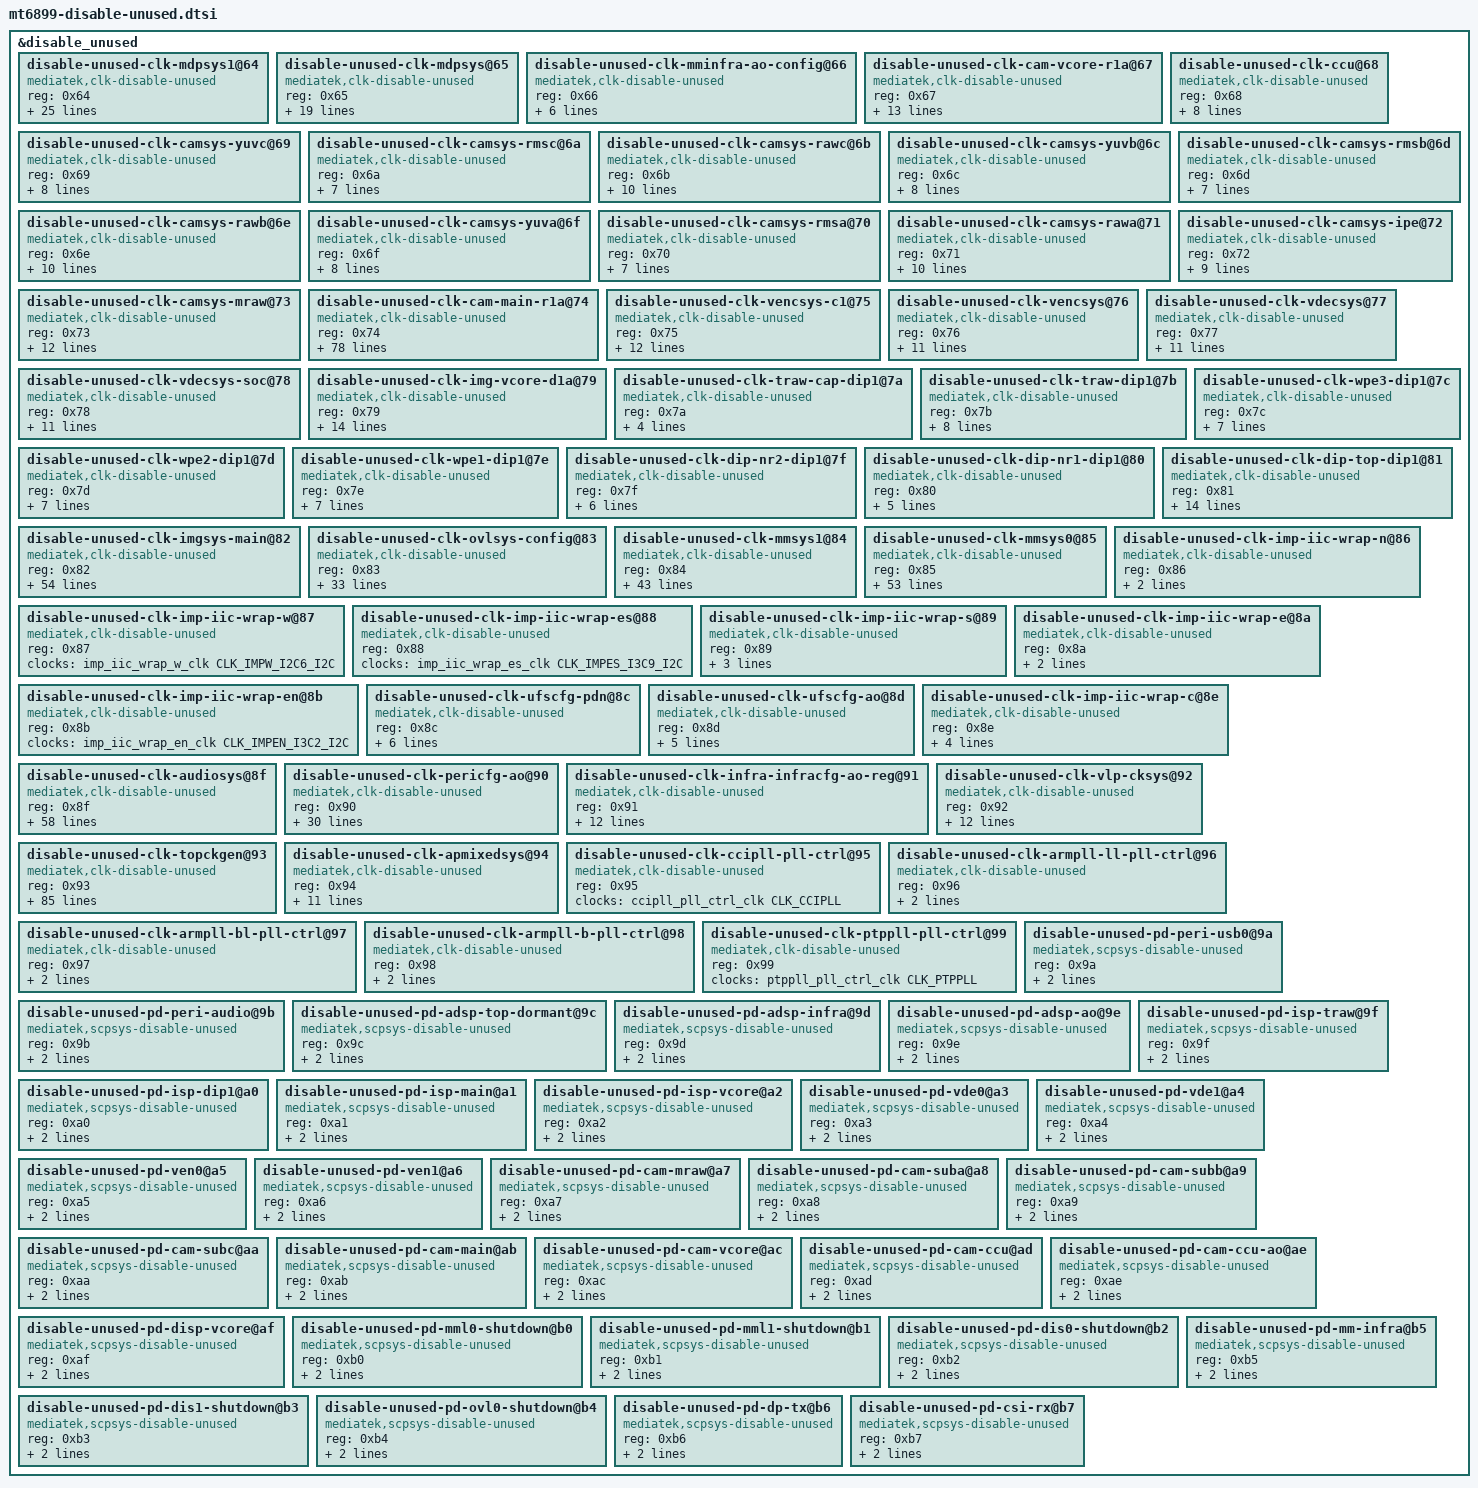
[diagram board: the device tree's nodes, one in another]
// SPDX-License-Identifier: (GPL-2.0 OR MIT)
/*
 * Copyright (C) 2024 MediaTek Inc.
 * Author: KY Liu <ky.liu@mediatek.com>
 */

&disable_unused {
	status = "okay";
	disable-unused-clk-mdpsys1@64 {
		compatible = "mediatek,clk-disable-unused";
		reg = <0x64>;
		clocks =
			<&mdpsys1_config_clk CLK_MDP1_MDP_MUTEX0_MML>,
			<&mdpsys1_config_clk CLK_MDP1_APB_BUS_MML>,
			<&mdpsys1_config_clk CLK_MDP1_SMI0_MML>,
			<&mdpsys1_config_clk CLK_MDP1_SMI0_SMI>,
			<&mdpsys1_config_clk CLK_MDP1_SMI0_GENPD>,
			<&mdpsys1_config_clk CLK_MDP1_MDP_RDMA0_MML>,
			<&mdpsys1_config_clk CLK_MDP1_MDP_RDMA2_MML>,
			<&mdpsys1_config_clk CLK_MDP1_MDP_HDR0_MML>,
			<&mdpsys1_config_clk CLK_MDP1_MDP_AAL0_MML>,
			<&mdpsys1_config_clk CLK_MDP1_MDP_RSZ0_MML>,
			<&mdpsys1_config_clk CLK_MDP1_MDP_TDSHP0_MML>,
			<&mdpsys1_config_clk CLK_MDP1_MDP_COLOR0_MML>,
			<&mdpsys1_config_clk CLK_MDP1_MDP_WROT0_MML>,
			<&mdpsys1_config_clk CLK_MDP1_MDP_FAKE_ENG0_MML>,
			<&mdpsys1_config_clk CLK_MDP1_MDP_DLI_ASYNC0_MML>,
			<&mdpsys1_config_clk CLK_MDP1_APB_DB_MML>,
			<&mdpsys1_config_clk CLK_MDP1_MDP_RSZ2_MML>,
			<&mdpsys1_config_clk CLK_MDP1_MDP_WROT2_MML>,
			<&mdpsys1_config_clk CLK_MDP1_MDP_DLO_ASYNC0_MML>,
			<&mdpsys1_config_clk CLK_MDP1_MDP_BIRSZ0_MML>,
			<&mdpsys1_config_clk CLK_MDP1_MDP_C3D0_MML>,
			<&mdpsys1_config_clk CLK_MDP1_MDP_FG0_MML>;
		power-domains = <&hfrpsys MT6899_POWER_DOMAIN_MML1_SHUTDOWN>;
	};

	disable-unused-clk-mdpsys@65 {
		compatible = "mediatek,clk-disable-unused";
		reg = <0x65>;
		clocks =
			<&mdpsys_config_clk CLK_MDP_MUTEX0_MML>,
			<&mdpsys_config_clk CLK_MDP_APB_BUS_MML>,
			<&mdpsys_config_clk CLK_MDP_SMI0_MML>,
			<&mdpsys_config_clk CLK_MDP_SMI0_SMI>,
			<&mdpsys_config_clk CLK_MDP_SMI0_GENPD>,
			<&mdpsys_config_clk CLK_MDP_RDMA0_MML>,
			<&mdpsys_config_clk CLK_MDP_RDMA2_MML>,
			<&mdpsys_config_clk CLK_MDP_HDR0_MML>,
			<&mdpsys_config_clk CLK_MDP_AAL0_MML>,
			<&mdpsys_config_clk CLK_MDP_RSZ0_MML>,
			<&mdpsys_config_clk CLK_MDP_TDSHP0_MML>,
			<&mdpsys_config_clk CLK_MDP_COLOR0_MML>,
			<&mdpsys_config_clk CLK_MDP_WROT0_MML>,
			<&mdpsys_config_clk CLK_MDP_FAKE_ENG0_MML>,
			<&mdpsys_config_clk CLK_MDP_APB_DB_MML>,
			<&mdpsys_config_clk CLK_MDP_BIRSZ0_MML>,
			<&mdpsys_config_clk CLK_MDP_C3D0_MML>;
		power-domains = <&hfrpsys MT6899_POWER_DOMAIN_MML0_SHUTDOWN>;
	};

	disable-unused-clk-mminfra-ao-config@66 {
		compatible = "mediatek,clk-disable-unused";
		reg = <0x66>;
		clocks =
			<&mminfra_ao_config_clk CLK_MMINFRA_AO_GCE_D_CMDQ>,
			<&mminfra_ao_config_clk CLK_MMINFRA_AO_GCE_M_CMDQ>,
			<&mminfra_ao_config_clk CLK_MMINFRA_AO_GCE_26M_CMDQ>;
		power-domains = <&hfrpsys MT6899_POWER_DOMAIN_MM_INFRA>;
	};

	disable-unused-clk-cam-vcore-r1a@67 {
		compatible = "mediatek,clk-disable-unused";
		reg = <0x67>;
		clocks =
			<&cam_vcore_r1a_clk CLK_CAMV_CV_CAMVCORE_CAMRAW>,
			<&cam_vcore_r1a_clk CLK_CAMV_CV_CAMVCORE_CAM_SENINF>,
			<&cam_vcore_r1a_clk CLK_CAMV_CV_CAM_26M_CAMRAW>,
			<&cam_vcore_r1a_clk CLK_CAMV_CV_CAM_26M_CAM_SENINF>,
			<&cam_vcore_r1a_clk CLK_CAMV_CV_CAM2MM0_SC_DCM_DIS_CAMRAW>,
			<&cam_vcore_r1a_clk CLK_CAMV_CV_CAM2MM0_SC_DCM_DIS_CAM_SENINF>,
			<&cam_vcore_r1a_clk CLK_CAMV_CV_MM0_SC_DCM_DIS_CCU>,
			<&cam_vcore_r1a_clk CLK_CAMV_CV_MM0_SC_DCM_DIS_CAMRAW>,
			<&cam_vcore_r1a_clk CLK_CAMV_CV_MM0_SC_DCM_DIS_CAM_SENINF>,
			<&cam_vcore_r1a_clk CLK_CAMV_CV_MM0_SC_DCM_DIS_SMI>;
		power-domains = <&hfrpsys MT6899_POWER_DOMAIN_CAM_MAIN>;
	};

	disable-unused-clk-ccu@68 {
		compatible = "mediatek,clk-disable-unused";
		reg = <0x68>;
		clocks =
			<&ccu_main_clk CLK_CCU_LARB19_CON_CCU>,
			<&ccu_main_clk CLK_CCU_LARB19_CON_SMI>,
			<&ccu_main_clk CLK_CCU_LARB19_CON_GENPD>,
			<&ccu_main_clk CLK_CCU2INFRA_GALS_CON_CCU>,
			<&ccu_main_clk CLK_CCUSYS_CCU0_CON_CCU0>,
			<&ccu_main_clk CLK_CCU2MM0_GALS_CON_CCU>;
		power-domains = <&hfrpsys MT6899_POWER_DOMAIN_CAM_VCORE>;
	};

	disable-unused-clk-camsys-yuvc@69 {
		compatible = "mediatek,clk-disable-unused";
		reg = <0x69>;
		clocks =
			<&camsys_yuvc_clk CLK_CAM_YC_LARBX_CAMRAWC>,
			<&camsys_yuvc_clk CLK_CAM_YC_LARBX_SMI>,
			<&camsys_yuvc_clk CLK_CAM_YC_LARBX_GENPD>,
			<&camsys_yuvc_clk CLK_CAM_YC_CAM_CAMRAWC>,
			<&camsys_yuvc_clk CLK_CAM_YC_CAMTG_CAMRAWC>;
		power-domains = <&hfrpsys MT6899_POWER_DOMAIN_CAM_MAIN>;
	};

	disable-unused-clk-camsys-rmsc@6a {
		compatible = "mediatek,clk-disable-unused";
		reg = <0x6a>;
		clocks =
			<&camsys_rmsc_clk CLK_CAMSYS_RMSC_LARBX_CAMRAWC>,
			<&camsys_rmsc_clk CLK_CAMSYS_RMSC_LARBX_SMI>,
			<&camsys_rmsc_clk CLK_CAMSYS_RMSC_CAM_CAMRAWC>,
			<&camsys_rmsc_clk CLK_CAMSYS_RMSC_CAMTG_CAMRAWC>;
		power-domains = <&hfrpsys MT6899_POWER_DOMAIN_CAM_MAIN>;
	};

	disable-unused-clk-camsys-rawc@6b {
		compatible = "mediatek,clk-disable-unused";
		reg = <0x6b>;
		clocks =
			<&camsys_rawc_clk CLK_CAM_RC_LARBX_CAMRAWC>,
			<&camsys_rawc_clk CLK_CAM_RC_LARBX_SMI>,
			<&camsys_rawc_clk CLK_CAM_RC_LARBX_GENPD>,
			<&camsys_rawc_clk CLK_CAM_RC_CAM_CAMRAWC>,
			<&camsys_rawc_clk CLK_CAM_RC_CAMTG_CAMRAWC>,
			<&camsys_rawc_clk CLK_CAM_RC_RAW2MM_GALS_CAMRAWC>,
			<&camsys_rawc_clk CLK_CAM_RC_YUV2RAW2MM_GALS_CAMRAWC>;
		power-domains = <&hfrpsys MT6899_POWER_DOMAIN_CAM_MAIN>;
	};

	disable-unused-clk-camsys-yuvb@6c {
		compatible = "mediatek,clk-disable-unused";
		reg = <0x6c>;
		clocks =
			<&camsys_yuvb_clk CLK_CAM_YB_LARBX_CAMRAWB>,
			<&camsys_yuvb_clk CLK_CAM_YB_LARBX_SMI>,
			<&camsys_yuvb_clk CLK_CAM_YB_LARBX_GENPD>,
			<&camsys_yuvb_clk CLK_CAM_YB_CAM_CAMRAWB>,
			<&camsys_yuvb_clk CLK_CAM_YB_CAMTG_CAMRAWB>;
		power-domains = <&hfrpsys MT6899_POWER_DOMAIN_CAM_MAIN>;
	};

	disable-unused-clk-camsys-rmsb@6d {
		compatible = "mediatek,clk-disable-unused";
		reg = <0x6d>;
		clocks =
			<&camsys_rmsb_clk CLK_CAMSYS_RMSB_LARBX_CAMRAWB>,
			<&camsys_rmsb_clk CLK_CAMSYS_RMSB_LARBX_SMI>,
			<&camsys_rmsb_clk CLK_CAMSYS_RMSB_CAM_CAMRAWB>,
			<&camsys_rmsb_clk CLK_CAMSYS_RMSB_CAMTG_CAMRAWB>;
		power-domains = <&hfrpsys MT6899_POWER_DOMAIN_CAM_MAIN>;
	};

	disable-unused-clk-camsys-rawb@6e {
		compatible = "mediatek,clk-disable-unused";
		reg = <0x6e>;
		clocks =
			<&camsys_rawb_clk CLK_CAM_RB_LARBX_CAMRAWB>,
			<&camsys_rawb_clk CLK_CAM_RB_LARBX_SMI>,
			<&camsys_rawb_clk CLK_CAM_RB_LARBX_GENPD>,
			<&camsys_rawb_clk CLK_CAM_RB_CAM_CAMRAWB>,
			<&camsys_rawb_clk CLK_CAM_RB_CAMTG_CAMRAWB>,
			<&camsys_rawb_clk CLK_CAM_RB_RAW2MM_GALS_CAMRAWB>,
			<&camsys_rawb_clk CLK_CAM_RB_YUV2RAW2MM_GALS_CAMRAWB>;
		power-domains = <&hfrpsys MT6899_POWER_DOMAIN_CAM_MAIN>;
	};

	disable-unused-clk-camsys-yuva@6f {
		compatible = "mediatek,clk-disable-unused";
		reg = <0x6f>;
		clocks =
			<&camsys_yuva_clk CLK_CAM_YA_LARBX_CAMRAWA>,
			<&camsys_yuva_clk CLK_CAM_YA_LARBX_SMI>,
			<&camsys_yuva_clk CLK_CAM_YA_LARBX_GENPD>,
			<&camsys_yuva_clk CLK_CAM_YA_CAM_CAMRAWA>,
			<&camsys_yuva_clk CLK_CAM_YA_CAMTG_CAMRAWA>;
		power-domains = <&hfrpsys MT6899_POWER_DOMAIN_CAM_MAIN>;
	};

	disable-unused-clk-camsys-rmsa@70 {
		compatible = "mediatek,clk-disable-unused";
		reg = <0x70>;
		clocks =
			<&camsys_rmsa_clk CLK_CAMSYS_RMSA_LARBX_CAMRAWA>,
			<&camsys_rmsa_clk CLK_CAMSYS_RMSA_LARBX_SMI>,
			<&camsys_rmsa_clk CLK_CAMSYS_RMSA_CAM_CAMRAWA>,
			<&camsys_rmsa_clk CLK_CAMSYS_RMSA_CAMTG_CAMRAWA>;
		power-domains = <&hfrpsys MT6899_POWER_DOMAIN_CAM_MAIN>;
	};

	disable-unused-clk-camsys-rawa@71 {
		compatible = "mediatek,clk-disable-unused";
		reg = <0x71>;
		clocks =
			<&camsys_rawa_clk CLK_CAM_RA_LARBX_CAMRAWA>,
			<&camsys_rawa_clk CLK_CAM_RA_LARBX_SMI>,
			<&camsys_rawa_clk CLK_CAM_RA_LARBX_GENPD>,
			<&camsys_rawa_clk CLK_CAM_RA_CAM_CAMRAWA>,
			<&camsys_rawa_clk CLK_CAM_RA_CAMTG_CAMRAWA>,
			<&camsys_rawa_clk CLK_CAM_RA_RAW2MM_GALS_CAMRAWA>,
			<&camsys_rawa_clk CLK_CAM_RA_YUV2RAW2MM_GALS_CAMRAWA>;
		power-domains = <&hfrpsys MT6899_POWER_DOMAIN_CAM_MAIN>;
	};

	disable-unused-clk-camsys-ipe@72 {
		compatible = "mediatek,clk-disable-unused";
		reg = <0x72>;
		clocks =
			<&camsys_ipe_clk CLK_CAMSYS_IPE_LARB19_SMI>,
			<&camsys_ipe_clk CLK_CAMSYS_IPE_LARB19_CAMERA_P2>,
			<&camsys_ipe_clk CLK_CAMSYS_IPE_LARB19_GENPD>,
			<&camsys_ipe_clk CLK_CAMSYS_IPE_DPE_CAMERA_P2>,
			<&camsys_ipe_clk CLK_CAMSYS_IPE_FUS_CAMERA_P2>,
			<&camsys_ipe_clk CLK_CAMSYS_IPE_GALS_CAMERA_P2>;
		power-domains = <&hfrpsys MT6899_POWER_DOMAIN_CAM_MAIN>;
	};

	disable-unused-clk-camsys-mraw@73 {
		compatible = "mediatek,clk-disable-unused";
		reg = <0x73>;
		clocks =
			<&camsys_mraw_clk CLK_CAM_MR_LARBX_PDAF>,
			<&camsys_mraw_clk CLK_CAM_MR_LARBX_SMI>,
			<&camsys_mraw_clk CLK_CAM_MR_LARBX_GENPD>,
			<&camsys_mraw_clk CLK_CAM_MR_GALS_PDAF>,
			<&camsys_mraw_clk CLK_CAM_MR_CAMTG_PDAF>,
			<&camsys_mraw_clk CLK_CAM_MR_MRAW0_PDAF>,
			<&camsys_mraw_clk CLK_CAM_MR_MRAW1_PDAF>,
			<&camsys_mraw_clk CLK_CAM_MR_MRAW2_PDAF>,
			<&camsys_mraw_clk CLK_CAM_MR_PDA0_PDAF>,
			<&camsys_mraw_clk CLK_CAM_MR_PDA1_PDAF>;
		power-domains = <&hfrpsys MT6899_POWER_DOMAIN_CAM_MAIN>;
	};

	disable-unused-clk-cam-main-r1a@74 {
		compatible = "mediatek,clk-disable-unused";
		reg = <0x74>;
		clocks =
			<&cam_main_r1a_clk CLK_CAM_MAIN_LARB13_CAMSV>,
			<&cam_main_r1a_clk CLK_CAM_MAIN_LARB13_SMI>,
			<&cam_main_r1a_clk CLK_CAM_MAIN_LARB13_GENPD>,
			<&cam_main_r1a_clk CLK_CAM_MAIN_LARB14_CAMSV>,
			<&cam_main_r1a_clk CLK_CAM_MAIN_LARB14_SMI>,
			<&cam_main_r1a_clk CLK_CAM_MAIN_LARB14_GENPD>,
			<&cam_main_r1a_clk CLK_CAM_MAIN_LARB27_SMI>,
			<&cam_main_r1a_clk CLK_CAM_MAIN_LARB27_GENPD>,
			<&cam_main_r1a_clk CLK_CAM_MAIN_LARB29_CAMSV>,
			<&cam_main_r1a_clk CLK_CAM_MAIN_LARB29_SMI>,
			<&cam_main_r1a_clk CLK_CAM_MAIN_LARB29_GENPD>,
			<&cam_main_r1a_clk CLK_CAM_MAIN_CAM_CAM_SENINF>,
			<&cam_main_r1a_clk CLK_CAM_MAIN_CAM_CAMRAWA>,
			<&cam_main_r1a_clk CLK_CAM_MAIN_CAM_CAMRAWB>,
			<&cam_main_r1a_clk CLK_CAM_MAIN_CAM_CAMRAWC>,
			<&cam_main_r1a_clk CLK_CAM_MAIN_CAM_CAMSV>,
			<&cam_main_r1a_clk CLK_CAM_MAIN_CAM_SUBA_CAMRAWA>,
			<&cam_main_r1a_clk CLK_CAM_MAIN_CAM_SUBA_GENPD>,
			<&cam_main_r1a_clk CLK_CAM_MAIN_CAM_SUBB_CAMRAWB>,
			<&cam_main_r1a_clk CLK_CAM_MAIN_CAM_SUBB_GENPD>,
			<&cam_main_r1a_clk CLK_CAM_MAIN_CAM_SUBC_CAMRAWC>,
			<&cam_main_r1a_clk CLK_CAM_MAIN_CAM_SUBC_GENPD>,
			<&cam_main_r1a_clk CLK_CAM_MAIN_CAM_MRAW_PDAF>,
			<&cam_main_r1a_clk CLK_CAM_MAIN_CAM_MRAW_GENPD>,
			<&cam_main_r1a_clk CLK_CAM_MAIN_CAMTG_CAM_SENINF>,
			<&cam_main_r1a_clk CLK_CAM_MAIN_CAMTG_CAMRAWA>,
			<&cam_main_r1a_clk CLK_CAM_MAIN_CAMTG_CAMRAWB>,
			<&cam_main_r1a_clk CLK_CAM_MAIN_CAMTG_CAMRAWC>,
			<&cam_main_r1a_clk CLK_CAM_MAIN_SENINF_CAM_SENINF>,
			<&cam_main_r1a_clk CLK_CAM_MAIN_CAMSV_TOP_CAMSV>,
			<&cam_main_r1a_clk CLK_CAM_MAIN_ADLRD_CAMRAWA>,
			<&cam_main_r1a_clk CLK_CAM_MAIN_ADLRD_CAMRAWB>,
			<&cam_main_r1a_clk CLK_CAM_MAIN_ADLRD_CAMRAWC>,
			<&cam_main_r1a_clk CLK_CAM_MAIN_ADLWR_CAMRAWA>,
			<&cam_main_r1a_clk CLK_CAM_MAIN_ADLWR_CAMRAWB>,
			<&cam_main_r1a_clk CLK_CAM_MAIN_ADLWR_CAMRAWC>,
			<&cam_main_r1a_clk CLK_CAM_MAIN_FAKE_ENG_CAMRAW>,
			<&cam_main_r1a_clk CLK_CAM_MAIN_CAM2MM0_GALS_CAMRAWA>,
			<&cam_main_r1a_clk CLK_CAM_MAIN_CAM2MM0_GALS_CAMRAWB>,
			<&cam_main_r1a_clk CLK_CAM_MAIN_CAM2MM0_GALS_CAMRAWC>,
			<&cam_main_r1a_clk CLK_CAM_MAIN_CAM2MM0_GALS_CAMSV>,
			<&cam_main_r1a_clk CLK_CAM_MAIN_CAM2MM0_GALS_PDAF>,
			<&cam_main_r1a_clk CLK_CAM_MAIN_CAM2MM1_GALS_CAMRAWA>,
			<&cam_main_r1a_clk CLK_CAM_MAIN_CAM2MM1_GALS_CAMRAWB>,
			<&cam_main_r1a_clk CLK_CAM_MAIN_CAM2MM1_GALS_CAMRAWC>,
			<&cam_main_r1a_clk CLK_CAM_MAIN_CAM2MM1_GALS_CAMSV>,
			<&cam_main_r1a_clk CLK_CAM_MAIN_CAM2MM1_GALS_PDAF>,
			<&cam_main_r1a_clk CLK_CAM_MAIN_CAM2SYS_GALS_CAMRAWA>,
			<&cam_main_r1a_clk CLK_CAM_MAIN_CAM2SYS_GALS_CAMRAWB>,
			<&cam_main_r1a_clk CLK_CAM_MAIN_CAM2SYS_GALS_CAMRAWC>,
			<&cam_main_r1a_clk CLK_CAM_MAIN_CAM2SYS_GALS_CAMSV>,
			<&cam_main_r1a_clk CLK_CAM_MAIN_CAM2SYS_GALS_PDAF>,
			<&cam_main_r1a_clk CLK_CAM_MAIN_CAM2MM2_GALS_CAMRAWA>,
			<&cam_main_r1a_clk CLK_CAM_MAIN_CAM2MM2_GALS_CAMRAWB>,
			<&cam_main_r1a_clk CLK_CAM_MAIN_CAM2MM2_GALS_CAMRAWC>,
			<&cam_main_r1a_clk CLK_CAM_MAIN_CAM2MM2_GALS_CAMSV>,
			<&cam_main_r1a_clk CLK_CAM_MAIN_CAM2MM2_GALS_PDAF>,
			<&cam_main_r1a_clk CLK_CAM_MAIN_IPS_CAMRAW>,
			<&cam_main_r1a_clk CLK_CAM_MAIN_CAM_DPE_CAMERA_P2>,
			<&cam_main_r1a_clk CLK_CAM_MAIN_CAM_DPE_GENPD>,
			<&cam_main_r1a_clk CLK_CAM_MAIN_CAM_ASG_CAM_SENINF>,
			<&cam_main_r1a_clk CLK_CAM_MAIN_CAMSV_A_CON_1_CAMSV>,
			<&cam_main_r1a_clk CLK_CAM_MAIN_CAMSV_B_CON_1_CAMSV>,
			<&cam_main_r1a_clk CLK_CAM_MAIN_CAMSV_C_CON_1_CAMSV>,
			<&cam_main_r1a_clk CLK_CAM_MAIN_CAMSV_D_CON_1_CAMSV>,
			<&cam_main_r1a_clk CLK_CAM_MAIN_CAMSV_E_CON_1_CAMSV>,
			<&cam_main_r1a_clk CLK_CAM_MAIN_CAM_QOF_CON_1_CAMRAW>,
			<&cam_main_r1a_clk CLK_CAM_MAIN_CAM_BLS_FULL_CON_1_CAMRAW>,
			<&cam_main_r1a_clk CLK_CAM_MAIN_CAM_BLS_PART_CON_1_CAMRAW>,
			<&cam_main_r1a_clk CLK_CAM_MAIN_CAM_BWR_CON_1_CAMBWR>,
			<&cam_main_r1a_clk CLK_CAM_MAIN_CAM_RTCQ_CON_1_CAMRAW>,
			<&cam_main_r1a_clk CLK_CAM_MAIN_CAM2MM0_SUB_COMMON_DCM_DIS_CAMRAW>,
			<&cam_main_r1a_clk CLK_CAM_MAIN_CAM2MM1_SUB_COMMON_DCM_DIS_CAMRAW>,
			<&cam_main_r1a_clk CLK_CAM_MAIN_CAM2SYS_SUB_COMMON_DCM_DIS_CAMRAW>,
			<&cam_main_r1a_clk CLK_CAM_MAIN_CAM2MM2_SUB_COMMON_DCM_DIS_CAMRAW>;
		power-domains = <&hfrpsys MT6899_POWER_DOMAIN_CAM_VCORE>;
	};

	disable-unused-clk-vencsys-c1@75 {
		compatible = "mediatek,clk-disable-unused";
		reg = <0x75>;
		clocks =
			<&venc_gcon_core1_clk CLK_VEN2_CKE0_LARB_VENC>,
			<&venc_gcon_core1_clk CLK_VEN2_CKE0_LARB_SMI>,
			<&venc_gcon_core1_clk CLK_VEN2_CKE1_VENC_VENC>,
			<&venc_gcon_core1_clk CLK_VEN2_CKE2_JPGENC_JPGENC>,
			<&venc_gcon_core1_clk CLK_VEN2_CKE3_JPGDEC_JPGDEC>,
			<&venc_gcon_core1_clk CLK_VEN2_CKE5_GALS_VENC>,
			<&venc_gcon_core1_clk CLK_VEN2_CKE5_GALS_SMI>,
			<&venc_gcon_core1_clk CLK_VEN2_CKE6_GALS_SRAM_VENC>,
			<&venc_gcon_core1_clk CLK_VEN2_CKE6_GALS_SRAM_SMI>;
		power-domains = <&hfrpsys MT6899_POWER_DOMAIN_VEN1>;
	};

	disable-unused-clk-vencsys@76 {
		compatible = "mediatek,clk-disable-unused";
		reg = <0x76>;
		clocks =
			<&venc_gcon_clk CLK_VEN1_CKE0_LARB_SMI>,
			<&venc_gcon_clk CLK_VEN1_CKE1_VENC_VENC>,
			<&venc_gcon_clk CLK_VEN1_CKE2_JPGENC_JPGENC>,
			<&venc_gcon_clk CLK_VEN1_CKE3_JPGDEC_JPGDEC>,
			<&venc_gcon_clk CLK_VEN1_CKE4_JPGDEC_C1_JPGDEC>,
			<&venc_gcon_clk CLK_VEN1_CKE5_GALS_VENC>,
			<&venc_gcon_clk CLK_VEN1_CKE5_GALS_SMI>,
			<&venc_gcon_clk CLK_VEN1_CKE6_GALS_SRAM_VENC>,
			<&venc_gcon_clk CLK_VEN1_CKE6_GALS_SRAM_SMI>;
		power-domains = <&hfrpsys MT6899_POWER_DOMAIN_VEN0>;
	};

	disable-unused-clk-vdecsys@77 {
		compatible = "mediatek,clk-disable-unused";
		reg = <0x77>;
		clocks =
			<&vdec_gcon_base_clk CLK_VDE2_LARB1_CKEN_SMI>,
			<&vdec_gcon_base_clk CLK_VDE2_LARB1_CKEN_GENPD>,
			<&vdec_gcon_base_clk CLK_VDE2_LAT_CKEN_VDEC>,
			<&vdec_gcon_base_clk CLK_VDE2_LAT_ACTIVE_VDEC>,
			<&vdec_gcon_base_clk CLK_VDE2_LAT_CKEN_ENG_VDEC>,
			<&vdec_gcon_base_clk CLK_VDE2_VDEC_CKEN_VDEC>,
			<&vdec_gcon_base_clk CLK_VDE2_VDEC_ACTIVE_VDEC>,
			<&vdec_gcon_base_clk CLK_VDE2_VDEC_CKEN_ENG_VDEC>;
		power-domains = <&hfrpsys MT6899_POWER_DOMAIN_VDE0>;
	};

	disable-unused-clk-vdecsys-soc@78 {
		compatible = "mediatek,clk-disable-unused";
		reg = <0x78>;
		clocks =
			<&vdec_soc_gcon_base_clk CLK_VDE1_LARB1_CKEN_SMI>,
			<&vdec_soc_gcon_base_clk CLK_VDE1_LARB1_CKEN_GENPD>,
			<&vdec_soc_gcon_base_clk CLK_VDE1_LAT_CKEN_VDEC>,
			<&vdec_soc_gcon_base_clk CLK_VDE1_LAT_ACTIVE_VDEC>,
			<&vdec_soc_gcon_base_clk CLK_VDE1_LAT_CKEN_ENG_VDEC>,
			<&vdec_soc_gcon_base_clk CLK_VDE1_VDEC_CKEN_VDEC>,
			<&vdec_soc_gcon_base_clk CLK_VDE1_VDEC_ACTIVE_VDEC>,
			<&vdec_soc_gcon_base_clk CLK_VDE1_VDEC_CKEN_ENG_VDEC>;
		power-domains = <&hfrpsys MT6899_POWER_DOMAIN_VDE1>;
	};

	disable-unused-clk-img-vcore-d1a@79 {
		compatible = "mediatek,clk-disable-unused";
		reg = <0x79>;
		clocks =
			<&img_vcore_d1a_clk CLK_IMG_VCORE_GALS_DISP_CAMERA_P2>,
			<&img_vcore_d1a_clk CLK_IMG_VCORE_GALS_DISP_CAMERA_MAE>,
			<&img_vcore_d1a_clk CLK_IMG_VCORE_MAIN_CAMERA_P2>,
			<&img_vcore_d1a_clk CLK_IMG_VCORE_MAIN_CAMERA_MAE>,
			<&img_vcore_d1a_clk CLK_IMG_VCORE_SUB0_CAMERA_P2>,
			<&img_vcore_d1a_clk CLK_IMG_VCORE_SUB0_CAMERA_MAE>,
			<&img_vcore_d1a_clk CLK_IMG_VCORE_SUB0_SMI>,
			<&img_vcore_d1a_clk CLK_IMG_VCORE_SUB1_CAMERA_P2>,
			<&img_vcore_d1a_clk CLK_IMG_VCORE_SUB1_CAMERA_MAE>,
			<&img_vcore_d1a_clk CLK_IMG_VCORE_SUB1_SMI>,
			<&img_vcore_d1a_clk CLK_IMG_VCORE_IMG_26M_CAMERA_P2>;
		power-domains = <&hfrpsys MT6899_POWER_DOMAIN_ISP_MAIN>;
	};

	disable-unused-clk-traw-cap-dip1@7a {
		compatible = "mediatek,clk-disable-unused";
		reg = <0x7a>;
		clocks =
			<&traw_cap_dip1_clk CLK_TRAW_CAP_DIP1_TRAW_CAP_CAMERA_P2>;
		power-domains = <&hfrpsys MT6899_POWER_DOMAIN_ISP_TRAW>;
	};

	disable-unused-clk-traw-dip1@7b {
		compatible = "mediatek,clk-disable-unused";
		reg = <0x7b>;
		clocks =
			<&traw_dip1_clk CLK_TRAW_DIP1_LARB28_CAMERA_P2>,
			<&traw_dip1_clk CLK_TRAW_DIP1_LARB28_SMI>,
			<&traw_dip1_clk CLK_TRAW_DIP1_LARB40_CAMERA_P2>,
			<&traw_dip1_clk CLK_TRAW_DIP1_TRAW_CAMERA_P2>,
			<&traw_dip1_clk CLK_TRAW_DIP1_GALS_CAMERA_P2>;
		power-domains = <&hfrpsys MT6899_POWER_DOMAIN_ISP_TRAW>;
	};

	disable-unused-clk-wpe3-dip1@7c {
		compatible = "mediatek,clk-disable-unused";
		reg = <0x7c>;
		clocks =
			<&wpe3_dip1_clk CLK_WPE3_DIP1_LARB11_CAMERA_P2>,
			<&wpe3_dip1_clk CLK_WPE3_DIP1_LARB11_SMI>,
			<&wpe3_dip1_clk CLK_WPE3_DIP1_WPE_CAMERA_P2>,
			<&wpe3_dip1_clk CLK_WPE3_DIP1_GALS0_CAMERA_P2>;
		power-domains = <&hfrpsys MT6899_POWER_DOMAIN_ISP_DIP1>;
	};

	disable-unused-clk-wpe2-dip1@7d {
		compatible = "mediatek,clk-disable-unused";
		reg = <0x7d>;
		clocks =
			<&wpe2_dip1_clk CLK_WPE2_DIP1_LARB11_CAMERA_P2>,
			<&wpe2_dip1_clk CLK_WPE2_DIP1_LARB11_SMI>,
			<&wpe2_dip1_clk CLK_WPE2_DIP1_WPE_CAMERA_P2>,
			<&wpe2_dip1_clk CLK_WPE2_DIP1_GALS0_CAMERA_P2>;
		power-domains = <&hfrpsys MT6899_POWER_DOMAIN_ISP_DIP1>;
	};

	disable-unused-clk-wpe1-dip1@7e {
		compatible = "mediatek,clk-disable-unused";
		reg = <0x7e>;
		clocks =
			<&wpe1_dip1_clk CLK_WPE1_DIP1_LARB11_CAMERA_P2>,
			<&wpe1_dip1_clk CLK_WPE1_DIP1_LARB11_SMI>,
			<&wpe1_dip1_clk CLK_WPE1_DIP1_WPE_CAMERA_P2>,
			<&wpe1_dip1_clk CLK_WPE1_DIP1_GALS0_CAMERA_P2>;
		power-domains = <&hfrpsys MT6899_POWER_DOMAIN_ISP_DIP1>;
	};

	disable-unused-clk-dip-nr2-dip1@7f {
		compatible = "mediatek,clk-disable-unused";
		reg = <0x7f>;
		clocks =
			<&dip_nr2_dip1_clk CLK_DIP_NR2_DIP1_DIP_NR_CAMERA_P2>,
			<&dip_nr2_dip1_clk CLK_DIP_NR2_DIP1_LARB15_CAMERA_P2>,
			<&dip_nr2_dip1_clk CLK_DIP_NR2_DIP1_LARB39_CAMERA_P2>;
		power-domains = <&hfrpsys MT6899_POWER_DOMAIN_ISP_DIP1>;
	};

	disable-unused-clk-dip-nr1-dip1@80 {
		compatible = "mediatek,clk-disable-unused";
		reg = <0x80>;
		clocks =
			<&dip_nr1_dip1_clk CLK_DIP_NR1_DIP1_LARB_CAMERA_P2>,
			<&dip_nr1_dip1_clk CLK_DIP_NR1_DIP1_DIP_NR1_CAMERA_P2>;
		power-domains = <&hfrpsys MT6899_POWER_DOMAIN_ISP_DIP1>;
	};

	disable-unused-clk-dip-top-dip1@81 {
		compatible = "mediatek,clk-disable-unused";
		reg = <0x81>;
		clocks =
			<&dip_top_dip1_clk CLK_DIP_TOP_DIP1_DIP_TOP_CAMERA_P2>,
			<&dip_top_dip1_clk CLK_DIP_TOP_DIP1_DIP_TOP_GALS0_CAMERA_P2>,
			<&dip_top_dip1_clk CLK_DIP_TOP_DIP1_DIP_TOP_GALS1_CAMERA_P2>,
			<&dip_top_dip1_clk CLK_DIP_TOP_DIP1_DIP_TOP_GALS2_CAMERA_P2>,
			<&dip_top_dip1_clk CLK_DIP_TOP_DIP1_DIP_TOP_GALS3_CAMERA_P2>,
			<&dip_top_dip1_clk CLK_DIP_TOP_DIP1_LARB10_CAMERA_P2>,
			<&dip_top_dip1_clk CLK_DIP_TOP_DIP1_LARB15_CAMERA_P2>,
			<&dip_top_dip1_clk CLK_DIP_TOP_DIP1_LARB15_SMI>,
			<&dip_top_dip1_clk CLK_DIP_TOP_DIP1_LARB38_CAMERA_P2>,
			<&dip_top_dip1_clk CLK_DIP_TOP_DIP1_LARB38_SMI>,
			<&dip_top_dip1_clk CLK_DIP_TOP_DIP1_LARB39_CAMERA_P2>;
		power-domains = <&hfrpsys MT6899_POWER_DOMAIN_ISP_DIP1>;
	};

	disable-unused-clk-imgsys-main@82 {
		compatible = "mediatek,clk-disable-unused";
		reg = <0x82>;
		clocks =
			<&imgsys_main_clk CLK_IMG_FDVT_CAMERA_MAE>,
			<&imgsys_main_clk CLK_IMG_ME_CAMERA_P2>,
			<&imgsys_main_clk CLK_IMG_MMG_CAMERA_P2>,
			<&imgsys_main_clk CLK_IMG_LARB12_CAMERA_P2>,
			<&imgsys_main_clk CLK_IMG_LARB12_SMI>,
			<&imgsys_main_clk CLK_IMG_LARB12_CAMERA_MAE>,
			<&imgsys_main_clk CLK_IMG_LARB9_CAMERA_P2>,
			<&imgsys_main_clk CLK_IMG_LARB9_SMI>,
			<&imgsys_main_clk CLK_IMG_TRAW0_CAMERA_P2>,
			<&imgsys_main_clk CLK_IMG_TRAW1_CAMERA_P2>,
			<&imgsys_main_clk CLK_IMG_DIP0_CAMERA_P2>,
			<&imgsys_main_clk CLK_IMG_WPE0_CAMERA_P2>,
			<&imgsys_main_clk CLK_IMG_IPE_CAMERA_P2>,
			<&imgsys_main_clk CLK_IMG_IPE_CAMERA_MAE>,
			<&imgsys_main_clk CLK_IMG_WPE1_CAMERA_P2>,
			<&imgsys_main_clk CLK_IMG_WPE2_CAMERA_P2>,
			<&imgsys_main_clk CLK_IMG_ADL_LARB_CAMERA_P2>,
			<&imgsys_main_clk CLK_IMG_ADL_LARB_SMI>,
			<&imgsys_main_clk CLK_IMG_ADLRD_CAMERA_P2>,
			<&imgsys_main_clk CLK_IMG_ADLWR0_CAMERA_P2>,
			<&imgsys_main_clk CLK_IMG_AVS_CAMERA_P2>,
			<&imgsys_main_clk CLK_IMG_IPS_CAMERA_P2>,
			<&imgsys_main_clk CLK_IMG_ADLWR1_CAMERA_P2>,
			<&imgsys_main_clk CLK_IMG_ROOTCQ_CAMERA_P2>,
			<&imgsys_main_clk CLK_IMG_BLS_CAMERA_P2>,
			<&imgsys_main_clk CLK_IMG_SUB_COMMON0_CAMERA_P2>,
			<&imgsys_main_clk CLK_IMG_SUB_COMMON0_SMI>,
			<&imgsys_main_clk CLK_IMG_SUB_COMMON1_CAMERA_P2>,
			<&imgsys_main_clk CLK_IMG_SUB_COMMON1_SMI>,
			<&imgsys_main_clk CLK_IMG_SUB_COMMON2_CAMERA_P2>,
			<&imgsys_main_clk CLK_IMG_SUB_COMMON2_CAMERA_MAE>,
			<&imgsys_main_clk CLK_IMG_SUB_COMMON2_SMI>,
			<&imgsys_main_clk CLK_IMG_SUB_COMMON3_CAMERA_P2>,
			<&imgsys_main_clk CLK_IMG_SUB_COMMON3_CAMERA_MAE>,
			<&imgsys_main_clk CLK_IMG_SUB_COMMON3_SMI>,
			<&imgsys_main_clk CLK_IMG_SUB_COMMON4_CAMERA_P2>,
			<&imgsys_main_clk CLK_IMG_SUB_COMMON4_SMI>,
			<&imgsys_main_clk CLK_IMG_GALS_RX_DIP0_CAMERA_P2>,
			<&imgsys_main_clk CLK_IMG_GALS_RX_DIP1_CAMERA_P2>,
			<&imgsys_main_clk CLK_IMG_GALS_RX_TRAW0_CAMERA_P2>,
			<&imgsys_main_clk CLK_IMG_GALS_RX_WPE0_CAMERA_P2>,
			<&imgsys_main_clk CLK_IMG_GALS_RX_WPE1_CAMERA_P2>,
			<&imgsys_main_clk CLK_IMG_GALS_RX_WPE2_CAMERA_P2>,
			<&imgsys_main_clk CLK_IMG_GALS_TRX_IPE0_CAMERA_P2>,
			<&imgsys_main_clk CLK_IMG_GALS_TRX_IPE0_CAMERA_MAE>,
			<&imgsys_main_clk CLK_IMG_GALS_TRX_IPE1_CAMERA_P2>,
			<&imgsys_main_clk CLK_IMG_GALS_TRX_IPE1_CAMERA_MAE>,
			<&imgsys_main_clk CLK_IMG26_CAMERA_P2>,
			<&imgsys_main_clk CLK_IMG_BWR_CAMERA_P2>,
			<&imgsys_main_clk CLK_IMG_GALS_CAMERA_P2>,
			<&imgsys_main_clk CLK_IMG_GALS_CAMERA_MAE>;
		power-domains = <&hfrpsys MT6899_POWER_DOMAIN_ISP_MAIN>;
	};

	disable-unused-clk-ovlsys-config@83 {
		compatible = "mediatek,clk-disable-unused";
		reg = <0x83>;
		clocks =
			<&ovlsys_config_clk CLK_OVLSYS_CONFIG_DISP>,
			<&ovlsys_config_clk CLK_OVL_DISP_FAKE_ENG0_DISP>,
			<&ovlsys_config_clk CLK_OVL_DISP_FAKE_ENG1_DISP>,
			<&ovlsys_config_clk CLK_OVL_DISP_MUTEX0_DISP>,
			<&ovlsys_config_clk CLK_OVL_DISP_OVL0_2L_DISP>,
			<&ovlsys_config_clk CLK_OVL_DISP_OVL1_2L_DISP>,
			<&ovlsys_config_clk CLK_OVL_DISP_OVL2_2L_DISP>,
			<&ovlsys_config_clk CLK_OVL_DISP_OVL3_2L_DISP>,
			<&ovlsys_config_clk CLK_OVL_DISP_RSZ1_DISP>,
			<&ovlsys_config_clk CLK_OVL_MDP_RSZ0_DISP>,
			<&ovlsys_config_clk CLK_OVL_DISP_WDMA0_DISP>,
			<&ovlsys_config_clk CLK_OVL_DISP_UFBC_WDMA0_DISP>,
			<&ovlsys_config_clk CLK_OVL_DISP_WDMA2_DISP>,
			<&ovlsys_config_clk CLK_OVL_DISP_DLI_ASYNC0_DISP>,
			<&ovlsys_config_clk CLK_OVL_DISP_DLI_ASYNC1_DISP>,
			<&ovlsys_config_clk CLK_OVL_DISP_DLI_ASYNC2_DISP>,
			<&ovlsys_config_clk CLK_OVL_DISP_DL0_ASYNC0_DISP>,
			<&ovlsys_config_clk CLK_OVL_DISP_DL0_ASYNC1_DISP>,
			<&ovlsys_config_clk CLK_OVL_DISP_DL0_ASYNC2_DISP>,
			<&ovlsys_config_clk CLK_OVL_DISP_DL0_ASYNC3_DISP>,
			<&ovlsys_config_clk CLK_OVL_DISP_DL0_ASYNC4_DISP>,
			<&ovlsys_config_clk CLK_OVL_DISP_DL0_ASYNC5_DISP>,
			<&ovlsys_config_clk CLK_OVL_DISP_DL0_ASYNC6_DISP>,
			<&ovlsys_config_clk CLK_OVL_INLINEROT0_DISP>,
			<&ovlsys_config_clk CLK_OVL_SMI_SUB_COMM0_DISP>,
			<&ovlsys_config_clk CLK_OVL_SMI_SUB_COMM0_SMI>,
			<&ovlsys_config_clk CLK_OVL_SMI_SUB_COMM0_GENPD>,
			<&ovlsys_config_clk CLK_OVL_DISP_Y2R0_DISP>,
			<&ovlsys_config_clk CLK_OVL_DISP_Y2R1_DISP>,
			<&ovlsys_config_clk CLK_OVL_DISP_OVL4_2L_DISP>;
		power-domains = <&hfrpsys MT6899_POWER_DOMAIN_OVL0_SHUTDOWN>;
	};

	disable-unused-clk-mmsys1@84 {
		compatible = "mediatek,clk-disable-unused";
		reg = <0x84>;
		clocks =
			<&dispsys1_config_clk CLK_MM1_DISPSYS1_CONFIG_DISP>,
			<&dispsys1_config_clk CLK_MM1_DISP_MUTEX0_DISP>,
			<&dispsys1_config_clk CLK_MM1_DISP_DLI_ASYNC0_DISP>,
			<&dispsys1_config_clk CLK_MM1_DISP_DLI_ASYNC1_DISP>,
			<&dispsys1_config_clk CLK_MM1_DISP_DLI_ASYNC2_DISP>,
			<&dispsys1_config_clk CLK_MM1_MDP_RDMA0_DISP>,
			<&dispsys1_config_clk CLK_MM1_DISP_R2Y0_DISP>,
			<&dispsys1_config_clk CLK_MM1_DISP_SPLITTER0_DISP>,
			<&dispsys1_config_clk CLK_MM1_DISP_SPLITTER1_DISP>,
			<&dispsys1_config_clk CLK_MM1_DISP_VDCM0_DISP>,
			<&dispsys1_config_clk CLK_MM1_DISP_DSC_WRAP0_DISP>,
			<&dispsys1_config_clk CLK_MM1_DISP_DSC_WRAP1_DISP>,
			<&dispsys1_config_clk CLK_MM1_DISP_DSC_WRAP2_DISP>,
			<&dispsys1_config_clk CLK_MM1_DISP_DP_INTF0_DISP>,
			<&dispsys1_config_clk CLK_MM1_DISP_DSI0_DISP>,
			<&dispsys1_config_clk CLK_MM1_DISP_DSI1_DISP>,
			<&dispsys1_config_clk CLK_MM1_DISP_DSI2_DISP>,
			<&dispsys1_config_clk CLK_MM1_DISP_MERGE0_DISP>,
			<&dispsys1_config_clk CLK_MM1_DISP_WDMA0_DISP>,
			<&dispsys1_config_clk CLK_MM1_SMI_SUB_COMM0_DISP>,
			<&dispsys1_config_clk CLK_MM1_SMI_SUB_COMM0_SMI>,
			<&dispsys1_config_clk CLK_MM1_SMI_SUB_COMM0_GENPD>,
			<&dispsys1_config_clk CLK_MM1_DISP_WDMA1_DISP>,
			<&dispsys1_config_clk CLK_MM1_DISP_WDMA2_DISP>,
			<&dispsys1_config_clk CLK_MM1_DISP_GDMA0_DISP>,
			<&dispsys1_config_clk CLK_MM1_DISP_DLI_ASYNC3_DISP>,
			<&dispsys1_config_clk CLK_MM1_DISP_DLI_ASYNC4_DISP>,
			<&dispsys1_config_clk CLK_MM1_MOD1_DISP>,
			<&dispsys1_config_clk CLK_MM1_MOD2_DISP>,
			<&dispsys1_config_clk CLK_MM1_MOD3_DISP>,
			<&dispsys1_config_clk CLK_MM1_MOD4_DISP>,
			<&dispsys1_config_clk CLK_MM1_MOD5_DISP>,
			<&dispsys1_config_clk CLK_MM1_MOD6_DISP>,
			<&dispsys1_config_clk CLK_MM1_MOD7_DISP>,
			<&dispsys1_config_clk CLK_MM1_SUBSYS_DISP>,
			<&dispsys1_config_clk CLK_MM1_DSI0_DISP>,
			<&dispsys1_config_clk CLK_MM1_DSI1_DISP>,
			<&dispsys1_config_clk CLK_MM1_DSI2_DISP>,
			<&dispsys1_config_clk CLK_MM1_DP_DISP>,
			<&dispsys1_config_clk CLK_MM1_F26M_DISP>;
		power-domains = <&hfrpsys MT6899_POWER_DOMAIN_DISP_VCORE>;
	};

	disable-unused-clk-mmsys0@85 {
		compatible = "mediatek,clk-disable-unused";
		reg = <0x85>;
		clocks =
			<&dispsys_config_clk CLK_MM_CONFIG_DISP>,
			<&dispsys_config_clk CLK_MM_DISP_MUTEX0_DISP>,
			<&dispsys_config_clk CLK_MM_DISP_AAL0_DISP>,
			<&dispsys_config_clk CLK_MM_DISP_AAL1_DISP>,
			<&dispsys_config_clk CLK_MM_DISP_C3D0_DISP>,
			<&dispsys_config_clk CLK_MM_DISP_C3D1_DISP>,
			<&dispsys_config_clk CLK_MM_DISP_CCORR0_DISP>,
			<&dispsys_config_clk CLK_MM_DISP_CCORR1_DISP>,
			<&dispsys_config_clk CLK_MM_DISP_CCORR2_DISP>,
			<&dispsys_config_clk CLK_MM_DISP_CCORR3_DISP>,
			<&dispsys_config_clk CLK_MM_DISP_CHIST0_DISP>,
			<&dispsys_config_clk CLK_MM_DISP_CHIST1_DISP>,
			<&dispsys_config_clk CLK_MM_DISP_COLOR0_DISP>,
			<&dispsys_config_clk CLK_MM_DISP_COLOR1_DISP>,
			<&dispsys_config_clk CLK_MM_DISP_DITHER0_DISP>,
			<&dispsys_config_clk CLK_MM_DISP_DITHER1_DISP>,
			<&dispsys_config_clk CLK_MM_DISP_DITHER2_DISP>,
			<&dispsys_config_clk CLK_MM_DLI_ASYNC0_DISP>,
			<&dispsys_config_clk CLK_MM_DLI_ASYNC1_DISP>,
			<&dispsys_config_clk CLK_MM_DLI_ASYNC2_DISP>,
			<&dispsys_config_clk CLK_MM_DLI_ASYNC3_DISP>,
			<&dispsys_config_clk CLK_MM_DLI_ASYNC4_DISP>,
			<&dispsys_config_clk CLK_MM_DLI_ASYNC5_DISP>,
			<&dispsys_config_clk CLK_MM_DLI_ASYNC6_DISP>,
			<&dispsys_config_clk CLK_MM_DLI_ASYNC7_DISP>,
			<&dispsys_config_clk CLK_MM_DLO_ASYNC0_DISP>,
			<&dispsys_config_clk CLK_MM_DLO_ASYNC1_DISP>,
			<&dispsys_config_clk CLK_MM_DLO_ASYNC2_DISP>,
			<&dispsys_config_clk CLK_MM_DLO_ASYNC3_DISP>,
			<&dispsys_config_clk CLK_MM_DLO_ASYNC4_DISP>,
			<&dispsys_config_clk CLK_MM_DISP_GAMMA0_DISP>,
			<&dispsys_config_clk CLK_MM_DISP_GAMMA1_DISP>,
			<&dispsys_config_clk CLK_MM_MDP_AAL0_DISP>,
			<&dispsys_config_clk CLK_MM_MDP_RDMA0_DISP>,
			<&dispsys_config_clk CLK_MM_DISP_ODDMR0_DISP>,
			<&dispsys_config_clk CLK_MM_DISP_POSTALIGN0_DISP>,
			<&dispsys_config_clk CLK_MM_DISP_POSTMASK0_DISP>,
			<&dispsys_config_clk CLK_MM_DISP_POSTMASK1_DISP>,
			<&dispsys_config_clk CLK_MM_DISP_RSZ0_DISP>,
			<&dispsys_config_clk CLK_MM_DISP_RSZ1_DISP>,
			<&dispsys_config_clk CLK_MM_DISP_SPR0_DISP>,
			<&dispsys_config_clk CLK_MM_DISP_TDSHP0_DISP>,
			<&dispsys_config_clk CLK_MM_DISP_TDSHP1_DISP>,
			<&dispsys_config_clk CLK_MM_DISP_WDMA1_DISP>,
			<&dispsys_config_clk CLK_MM_DISP_Y2R0_DISP>,
			<&dispsys_config_clk CLK_MM_MDP_AAL1_DISP>,
			<&dispsys_config_clk CLK_MM_SMI_SUB_COMM0_DISP>,
			<&dispsys_config_clk CLK_MM_SMI_SUB_COMM0_SMI>,
			<&dispsys_config_clk CLK_MM_SMI_SUB_COMM0_GENPD>,
			<&dispsys_config_clk CLK_MM_DISP_RSZ0_MOUT_RELAY_DISP>,
			<&dispsys_config_clk CLK_MM_DISP_RSZ1_MOUT_RELAY_DISP>;
		power-domains = <&hfrpsys MT6899_POWER_DOMAIN_DIS1_SHUTDOWN>;
	};

	disable-unused-clk-imp-iic-wrap-n@86 {
		compatible = "mediatek,clk-disable-unused";
		reg = <0x86>;
		clocks =
			<&imp_iic_wrap_n_clk CLK_IMPN_I2C3_I2C>,
			<&imp_iic_wrap_n_clk CLK_IMPN_I2C5_I2C>;
	};

	disable-unused-clk-imp-iic-wrap-w@87 {
		compatible = "mediatek,clk-disable-unused";
		reg = <0x87>;
		clocks =
			<&imp_iic_wrap_w_clk CLK_IMPW_I2C6_I2C>;
	};

	disable-unused-clk-imp-iic-wrap-es@88 {
		compatible = "mediatek,clk-disable-unused";
		reg = <0x88>;
		clocks =
			<&imp_iic_wrap_es_clk CLK_IMPES_I3C9_I2C>;
	};

	disable-unused-clk-imp-iic-wrap-s@89 {
		compatible = "mediatek,clk-disable-unused";
		reg = <0x89>;
		clocks =
			<&imp_iic_wrap_s_clk CLK_IMPS_I3C0_I2C>,
			<&imp_iic_wrap_s_clk CLK_IMPS_I3C1_I2C>,
			<&imp_iic_wrap_s_clk CLK_IMPS_I3C7_I2C>;
	};

	disable-unused-clk-imp-iic-wrap-e@8a {
		compatible = "mediatek,clk-disable-unused";
		reg = <0x8a>;
		clocks =
			<&imp_iic_wrap_e_clk CLK_IMPE_I3C4_I2C>,
			<&imp_iic_wrap_e_clk CLK_IMPE_I3C8_I2C>;
	};

	disable-unused-clk-imp-iic-wrap-en@8b {
		compatible = "mediatek,clk-disable-unused";
		reg = <0x8b>;
		clocks =
			<&imp_iic_wrap_en_clk CLK_IMPEN_I3C2_I2C>;
	};

	disable-unused-clk-ufscfg-pdn@8c {
		compatible = "mediatek,clk-disable-unused";
		reg = <0x8c>;
		clocks =
			<&ufscfg_pdn_clk CLK_UFSPDN_UFSHCI_UFS_UFS>,
			<&ufscfg_pdn_clk CLK_UFSPDN_UFSHCI_AES_UFS>,
			<&ufscfg_pdn_clk CLK_UFSPDN_UFSHCI_U_AHB_UFS>,
			<&ufscfg_pdn_clk CLK_UFSPDN_UFSHCI_U_AXI_UFS>,
			<&ufscfg_pdn_clk CLK_UFSPDN_U_FREE_26M_UFS>;
	};

	disable-unused-clk-ufscfg-ao@8d {
		compatible = "mediatek,clk-disable-unused";
		reg = <0x8d>;
		clocks =
			<&ufscfg_ao_clk CLK_UFSAO_UNIPRO_SYS_UFS>,
			<&ufscfg_ao_clk CLK_UFSAO_U_PHY_SAP_UFS>,
			<&ufscfg_ao_clk CLK_UFSAO_U_PHY_TOP_AHB_S_BUSCK_UFS>,
			<&ufscfg_ao_clk CLK_UFSAO_U_AO_FREE_26M_UFS>;
	};

	disable-unused-clk-imp-iic-wrap-c@8e {
		compatible = "mediatek,clk-disable-unused";
		reg = <0x8e>;
		clocks =
			<&imp_iic_wrap_c_clk CLK_IMPC_I2C10_I2C>,
			<&imp_iic_wrap_c_clk CLK_IMPC_I2C11_I2C>,
			<&imp_iic_wrap_c_clk CLK_IMPC_I2C12_I2C>,
			<&imp_iic_wrap_c_clk CLK_IMPC_I2C13_I2C>;
	};

	disable-unused-clk-audiosys@8f {
		compatible = "mediatek,clk-disable-unused";
		reg = <0x8f>;
		clocks =
			<&afe_clk CLK_AFE_DL1_DAC_TML_AFE>,
			<&afe_clk CLK_AFE_DL1_DAC_HIRES_AFE>,
			<&afe_clk CLK_AFE_DL1_DAC_AFE>,
			<&afe_clk CLK_AFE_DL1_PREDIS_AFE>,
			<&afe_clk CLK_AFE_DL1_NLE_AFE>,
			<&afe_clk CLK_AFE_DL0_DAC_TML_AFE>,
			<&afe_clk CLK_AFE_DL0_DAC_HIRES_AFE>,
			<&afe_clk CLK_AFE_DL0_DAC_AFE>,
			<&afe_clk CLK_AFE_DL0_PREDIS_AFE>,
			<&afe_clk CLK_AFE_DL0_NLE_AFE>,
			<&afe_clk CLK_AFE_PCM1_AFE>,
			<&afe_clk CLK_AFE_PCM0_AFE>,
			<&afe_clk CLK_AFE_CM1_AFE>,
			<&afe_clk CLK_AFE_CM0_AFE>,
			<&afe_clk CLK_AFE_STF_AFE>,
			<&afe_clk CLK_AFE_HW_GAIN23_AFE>,
			<&afe_clk CLK_AFE_HW_GAIN01_AFE>,
			<&afe_clk CLK_AFE_FM_I2S_AFE>,
			<&afe_clk CLK_AFE_MTKAIFV4_AFE>,
			<&afe_clk CLK_AFE_DMIC1_ADC_HIRES_TML_AFE>,
			<&afe_clk CLK_AFE_DMIC1_ADC_HIRES_AFE>,
			<&afe_clk CLK_AFE_DMIC1_TML_AFE>,
			<&afe_clk CLK_AFE_DMIC1_ADC_AFE>,
			<&afe_clk CLK_AFE_DMIC0_ADC_HIRES_TML_AFE>,
			<&afe_clk CLK_AFE_DMIC0_ADC_HIRES_AFE>,
			<&afe_clk CLK_AFE_DMIC0_TML_AFE>,
			<&afe_clk CLK_AFE_DMIC0_ADC_AFE>,
			<&afe_clk CLK_AFE_UL1_ADC_HIRES_TML_AFE>,
			<&afe_clk CLK_AFE_UL1_ADC_HIRES_AFE>,
			<&afe_clk CLK_AFE_UL1_TML_AFE>,
			<&afe_clk CLK_AFE_UL1_ADC_AFE>,
			<&afe_clk CLK_AFE_UL0_TML_AFE>,
			<&afe_clk CLK_AFE_UL0_ADC_AFE>,
			<&afe_clk CLK_AFE_ETDM_IN6_AFE>,
			<&afe_clk CLK_AFE_ETDM_IN4_AFE>,
			<&afe_clk CLK_AFE_ETDM_IN2_AFE>,
			<&afe_clk CLK_AFE_ETDM_IN1_AFE>,
			<&afe_clk CLK_AFE_ETDM_IN0_AFE>,
			<&afe_clk CLK_AFE_ETDM_OUT6_AFE>,
			<&afe_clk CLK_AFE_ETDM_OUT4_AFE>,
			<&afe_clk CLK_AFE_ETDM_OUT2_AFE>,
			<&afe_clk CLK_AFE_ETDM_OUT1_AFE>,
			<&afe_clk CLK_AFE_ETDM_OUT0_AFE>,
			<&afe_clk CLK_AFE_TDM_OUT_AFE>,
			<&afe_clk CLK_AFE_GENERAL3_ASRC_AFE>,
			<&afe_clk CLK_AFE_GENERAL2_ASRC_AFE>,
			<&afe_clk CLK_AFE_GENERAL1_ASRC_AFE>,
			<&afe_clk CLK_AFE_GENERAL0_ASRC_AFE>,
			<&afe_clk CLK_AFE_CONNSYS_I2S_ASRC_AFE>,
			<&afe_clk CLK_AFE_AUDIO_HOPPING_AFE>,
			<&afe_clk CLK_AFE_AUDIO_F26M_AFE>,
			<&afe_clk CLK_AFE_APLL1_AFE>,
			<&afe_clk CLK_AFE_APLL2_AFE>,
			<&afe_clk CLK_AFE_H208M_AFE>,
			<&afe_clk CLK_AFE_APLL_TUNER2_AFE>,
			<&afe_clk CLK_AFE_APLL_TUNER1_AFE>;
		power-domains = <&scpsys MT6899_POWER_DOMAIN_PERI_AUDIO>;
	};

	disable-unused-clk-pericfg-ao@90 {
		compatible = "mediatek,clk-disable-unused";
		reg = <0x90>;
		clocks =
			<&pericfg_ao_clk CLK_PERAOP_UART0_UART>,
			<&pericfg_ao_clk CLK_PERAOP_UART1_UART>,
			<&pericfg_ao_clk CLK_PERAOP_UART2_UART>,
			<&pericfg_ao_clk CLK_PERAOP_UART3_UART>,
			<&pericfg_ao_clk CLK_PERAOP_PWM_H_PWM>,
			<&pericfg_ao_clk CLK_PERAOP_PWM_B_PWM>,
			<&pericfg_ao_clk CLK_PERAOP_PWM_FB1_PWM>,
			<&pericfg_ao_clk CLK_PERAOP_PWM_FB2_PWM>,
			<&pericfg_ao_clk CLK_PERAOP_PWM_FB3_PWM>,
			<&pericfg_ao_clk CLK_PERAOP_PWM_FB4_PWM>,
			<&pericfg_ao_clk CLK_PERAOP_SPI0_B_SPI>,
			<&pericfg_ao_clk CLK_PERAOP_SPI1_B_SPI>,
			<&pericfg_ao_clk CLK_PERAOP_SPI2_B_SPI>,
			<&pericfg_ao_clk CLK_PERAOP_SPI3_B_SPI>,
			<&pericfg_ao_clk CLK_PERAOP_SPI4_B_SPI>,
			<&pericfg_ao_clk CLK_PERAOP_SPI5_B_SPI>,
			<&pericfg_ao_clk CLK_PERAOP_SPI6_B_SPI>,
			<&pericfg_ao_clk CLK_PERAOP_SPI7_B_SPI>,
			<&pericfg_ao_clk CLK_PERAOP_DMA_B_UART>,
			<&pericfg_ao_clk CLK_PERAOP_DMA_B_I2C>,
			<&pericfg_ao_clk CLK_PERAOP_SSUSB0_FRMCNT_USB>,
			<&pericfg_ao_clk CLK_PERAOP_MSDC1_MSDC1>,
			<&pericfg_ao_clk CLK_PERAOP_MSDC1_F_MSDC1>,
			<&pericfg_ao_clk CLK_PERAOP_MSDC1_H_MSDC1>,
			<&pericfg_ao_clk CLK_PERAOP_MSDC2_MSDC2>,
			<&pericfg_ao_clk CLK_PERAOP_MSDC2_F_MSDC2>,
			<&pericfg_ao_clk CLK_PERAOP_MSDC2_H_MSDC2>,
			<&pericfg_ao_clk CLK_PERAOP_AUDIO_SLV_AFE>,
			<&pericfg_ao_clk CLK_PERAOP_AUDIO_MST_AFE>,
			<&pericfg_ao_clk CLK_PERAOP_AUDIO_INTBUS_AFE>;
	};

	disable-unused-clk-infra-infracfg-ao-reg@91 {
		compatible = "mediatek,clk-disable-unused";
		reg = <0x91>;
		clocks =
			<&infra_infracfg_ao_reg_clk CLK_INFRACFG_AO_CCIF1_AP_CCCI>,
			<&infra_infracfg_ao_reg_clk CLK_INFRACFG_AO_CCIF1_MD_CCCI>,
			<&infra_infracfg_ao_reg_clk CLK_INFRACFG_AO_CCIF_AP_CCCI>,
			<&infra_infracfg_ao_reg_clk CLK_INFRACFG_AO_CCIF_MD_CCCI>,
			<&infra_infracfg_ao_reg_clk CLK_INFRACFG_AO_CLDMA_BCLK_DPMAIF>,
			<&infra_infracfg_ao_reg_clk CLK_INFRACFG_AO_CCIF5_MD_CCCI>,
			<&infra_infracfg_ao_reg_clk CLK_INFRACFG_AO_CCIF2_AP_CCCI>,
			<&infra_infracfg_ao_reg_clk CLK_INFRACFG_AO_CCIF2_MD_CCCI>,
			<&infra_infracfg_ao_reg_clk CLK_INFRACFG_AO_DPMAIF_MAIN_DPMAIF>,
			<&infra_infracfg_ao_reg_clk CLK_INFRACFG_AO_CCIF4_MD_CCCI>,
			<&infra_infracfg_ao_reg_clk CLK_INFRACFG_AO_RG_MMW_DPMAIF26M_DPMAIF>;
	};

	disable-unused-clk-vlp-cksys@92 {
		compatible = "mediatek,clk-disable-unused";
		reg = <0x92>;
		clocks =
			<&vlp_cksys_clk CLK_VLP_CK_SCP_SEL>,
			<&vlp_cksys_clk CLK_VLP_CK_PWM_VLP_SEL>,
			<&vlp_cksys_clk CLK_VLP_CK_SSPM_SEL>,
			<&vlp_cksys_clk CLK_VLP_CK_IPS_SEL>,
			<&vlp_cksys_clk CLK_VLP_CK_CAMTG0_SEL>,
			<&vlp_cksys_clk CLK_VLP_CK_CAMTG1_SEL>,
			<&vlp_cksys_clk CLK_VLP_CK_CAMTG2_SEL>,
			<&vlp_cksys_clk CLK_VLP_CK_CAMTG3_SEL>,
			<&vlp_cksys_clk CLK_VLP_CK_CAMTG4_SEL>,
			<&vlp_cksys_clk CLK_VLP_CK_CAMTG5_SEL>,
			<&vlp_cksys_clk CLK_VLP_CK_CAMTG6_SEL>,
			<&vlp_cksys_clk CLK_VLP_CK_CAMTG7_SEL>;
	};

	disable-unused-clk-topckgen@93 {
		compatible = "mediatek,clk-disable-unused";
		reg = <0x93>;
		clocks =
			<&topckgen_clk CLK_TOP_APLL12_CK_DIV_I2SIN0>,
			<&topckgen_clk CLK_TOP_APLL12_CK_DIV_I2SIN1>,
			<&topckgen_clk CLK_TOP_APLL12_CK_DIV_I2SIN2>,
			<&topckgen_clk CLK_TOP_APLL12_CK_DIV_I2SIN3>,
			<&topckgen_clk CLK_TOP_APLL12_CK_DIV_I2SIN4>,
			<&topckgen_clk CLK_TOP_APLL12_CK_DIV_I2SIN6>,
			<&topckgen_clk CLK_TOP_APLL12_CK_DIV_I2SOUT0>,
			<&topckgen_clk CLK_TOP_APLL12_CK_DIV_I2SOUT1>,
			<&topckgen_clk CLK_TOP_APLL12_CK_DIV_I2SOUT2>,
			<&topckgen_clk CLK_TOP_APLL12_CK_DIV_I2SOUT3>,
			<&topckgen_clk CLK_TOP_APLL12_CK_DIV_I2SOUT4>,
			<&topckgen_clk CLK_TOP_APLL12_CK_DIV_I2SOUT6>,
			<&topckgen_clk CLK_TOP_APLL12_CK_DIV_FMI2S>,
			<&topckgen_clk CLK_TOP_APLL12_CK_DIV_TDMOUT_M>,
			<&topckgen_clk CLK_TOP_APLL12_CK_DIV_TDMOUT_B>,
			<&topckgen_clk CLK_TOP_DSP_SEL>,
			<&topckgen_clk CLK_TOP_UART_SEL>,
			<&topckgen_clk CLK_TOP_SPI0_BCLK_SEL>,
			<&topckgen_clk CLK_TOP_SPI1_BCLK_SEL>,
			<&topckgen_clk CLK_TOP_SPI2_BCLK_SEL>,
			<&topckgen_clk CLK_TOP_SPI3_BCLK_SEL>,
			<&topckgen_clk CLK_TOP_SPI4_BCLK_SEL>,
			<&topckgen_clk CLK_TOP_SPI5_BCLK_SEL>,
			<&topckgen_clk CLK_TOP_SPI6_BCLK_SEL>,
			<&topckgen_clk CLK_TOP_SPI7_BCLK_SEL>,
			<&topckgen_clk CLK_TOP_MSDC30_1_SEL>,
			<&topckgen_clk CLK_TOP_MSDC30_2_SEL>,
			<&topckgen_clk CLK_TOP_AUD_INTBUS_SEL>,
			<&topckgen_clk CLK_TOP_USB_TOP_SEL>,
			<&topckgen_clk CLK_TOP_USB_XHCI_SEL>,
			<&topckgen_clk CLK_TOP_MSDC30_1_HCLK_SEL>,
			<&topckgen_clk CLK_TOP_I2C_SEL>,
			<&topckgen_clk CLK_TOP_AUD_ENGEN1_SEL>,
			<&topckgen_clk CLK_TOP_AUD_ENGEN2_SEL>,
			<&topckgen_clk CLK_TOP_U_SEL>,
			<&topckgen_clk CLK_TOP_U_MBIST_SEL>,
			<&topckgen_clk CLK_TOP_PEXTP_MBIST_SEL>,
			<&topckgen_clk CLK_TOP_AUD_1_SEL>,
			<&topckgen_clk CLK_TOP_AUD_2_SEL>,
			<&topckgen_clk CLK_TOP_AUDIO_H_SEL>,
			<&topckgen_clk CLK_TOP_ADSP_SEL>,
			<&topckgen_clk CLK_TOP_ADPS_UARTHUB_BCLK_SEL>,
			<&topckgen_clk CLK_TOP_DPMAIF_MAIN_SEL>,
			<&topckgen_clk CLK_TOP_PWM_SEL>,
			<&topckgen_clk CLK_TOP_MSDC30_2_HCLK_SEL>,
			<&topckgen_clk CLK_TOP_APLL_I2SIN0_MCK_SEL>,
			<&topckgen_clk CLK_TOP_APLL_I2SIN1_MCK_SEL>,
			<&topckgen_clk CLK_TOP_APLL_I2SIN2_MCK_SEL>,
			<&topckgen_clk CLK_TOP_APLL_I2SIN3_MCK_SEL>,
			<&topckgen_clk CLK_TOP_APLL_I2SIN4_MCK_SEL>,
			<&topckgen_clk CLK_TOP_APLL_I2SIN6_MCK_SEL>,
			<&topckgen_clk CLK_TOP_APLL_I2SOUT0_MCK_SEL>,
			<&topckgen_clk CLK_TOP_APLL_I2SOUT1_MCK_SEL>,
			<&topckgen_clk CLK_TOP_APLL_I2SOUT2_MCK_SEL>,
			<&topckgen_clk CLK_TOP_APLL_I2SOUT3_MCK_SEL>,
			<&topckgen_clk CLK_TOP_APLL_I2SOUT4_MCK_SEL>,
			<&topckgen_clk CLK_TOP_APLL_I2SOUT6_MCK_SEL>,
			<&topckgen_clk CLK_TOP_APLL_FMI2S_MCK_SEL>,
			<&topckgen_clk CLK_TOP_APLL_TDMOUT_MCK_SEL>,
			<&topckgen_clk CLK_TOP_SENINF0_SEL>,
			<&topckgen_clk CLK_TOP_SENINF1_SEL>,
			<&topckgen_clk CLK_TOP_SENINF2_SEL>,
			<&topckgen_clk CLK_TOP_SENINF3_SEL>,
			<&topckgen_clk CLK_TOP_SENINF4_SEL>,
			<&topckgen_clk CLK_TOP_SENINF5_SEL>,
			<&topckgen_clk CLK_TOP_CCU_AHB_SEL>,
			<&topckgen_clk CLK_TOP_IMG1_SEL>,
			<&topckgen_clk CLK_TOP_IPE_SEL>,
			<&topckgen_clk CLK_TOP_CAM_SEL>,
			<&topckgen_clk CLK_TOP_CAMTM_SEL>,
			<&topckgen_clk CLK_TOP_DPE_SEL>,
			<&topckgen_clk CLK_TOP_VDEC_SEL>,
			<&topckgen_clk CLK_TOP_CCUSYS_SEL>,
			<&topckgen_clk CLK_TOP_CCUTM_SEL>,
			<&topckgen_clk CLK_TOP_VENC_SEL>,
			<&topckgen_clk CLK_TOP_DP_CORE_SEL>,
			<&topckgen_clk CLK_TOP_DP_SEL>,
			<&topckgen_clk CLK_TOP_DISP_SEL>,
			<&topckgen_clk CLK_TOP_MDP_SEL>,
			<&topckgen_clk CLK_TOP_MMINFRA_SEL>,
			<&topckgen_clk CLK_TOP_MMUP_SEL>,
			<&topckgen_clk CLK_TOP_IMG_26M_SEL>,
			<&topckgen_clk CLK_TOP_CAM_26M_SEL>,
			<&topckgen_clk CLK_TOP_DSI_OCC_SEL>;
	};

	disable-unused-clk-apmixedsys@94 {
		compatible = "mediatek,clk-disable-unused";
		reg = <0x94>;
		clocks =
			<&apmixedsys_clk CLK_APMIXED_MAINPLL>,
			<&apmixedsys_clk CLK_APMIXED_UNIVPLL>,
			<&apmixedsys_clk CLK_APMIXED_MMPLL>,
			<&apmixedsys_clk CLK_APMIXED_EMIPLL>,
			<&apmixedsys_clk CLK_APMIXED_APLL1>,
			<&apmixedsys_clk CLK_APMIXED_APLL2>,
			<&apmixedsys_clk CLK_APMIXED_MSDCPLL>,
			<&apmixedsys_clk CLK_APMIXED_EMIPLL2>,
			<&apmixedsys_clk CLK_APMIXED_IMGPLL>,
			<&apmixedsys_clk CLK_APMIXED_TVDPLL>,
			<&apmixedsys_clk CLK_APMIXED_ADSPPLL>;
	};

	disable-unused-clk-ccipll-pll-ctrl@95 {
		compatible = "mediatek,clk-disable-unused";
		reg = <0x95>;
		clocks =
			<&ccipll_pll_ctrl_clk CLK_CCIPLL>;
	};

	disable-unused-clk-armpll-ll-pll-ctrl@96 {
		compatible = "mediatek,clk-disable-unused";
		reg = <0x96>;
		clocks =
			<&armpll_ll_pll_ctrl_clk CLK_CPU_LL_ARMPLL_LL>;
	};

	disable-unused-clk-armpll-bl-pll-ctrl@97 {
		compatible = "mediatek,clk-disable-unused";
		reg = <0x97>;
		clocks =
			<&armpll_bl_pll_ctrl_clk CLK_CPU_BL_ARMPLL_BL>;
	};

	disable-unused-clk-armpll-b-pll-ctrl@98 {
		compatible = "mediatek,clk-disable-unused";
		reg = <0x98>;
		clocks =
			<&armpll_b_pll_ctrl_clk CLK_CPU_B_ARMPLL_B>;
	};

	disable-unused-clk-ptppll-pll-ctrl@99 {
		compatible = "mediatek,clk-disable-unused";
		reg = <0x99>;
		clocks =
			<&ptppll_pll_ctrl_clk CLK_PTPPLL>;
	};

	disable-unused-pd-peri-usb0@9a {
		compatible = "mediatek,scpsys-disable-unused";
		reg = <0x9a>;
		power-domains = <&scpsys MT6899_POWER_DOMAIN_PERI_USB0>;
	};

	disable-unused-pd-peri-audio@9b {
		compatible = "mediatek,scpsys-disable-unused";
		reg = <0x9b>;
		power-domains = <&scpsys MT6899_POWER_DOMAIN_PERI_AUDIO>;
	};

	disable-unused-pd-adsp-top-dormant@9c {
		compatible = "mediatek,scpsys-disable-unused";
		reg = <0x9c>;
		power-domains = <&scpsys MT6899_POWER_DOMAIN_ADSP_TOP_DORMANT>;
	};

	disable-unused-pd-adsp-infra@9d {
		compatible = "mediatek,scpsys-disable-unused";
		reg = <0x9d>;
		power-domains = <&scpsys MT6899_POWER_DOMAIN_ADSP_INFRA>;
	};

	disable-unused-pd-adsp-ao@9e {
		compatible = "mediatek,scpsys-disable-unused";
		reg = <0x9e>;
		power-domains = <&scpsys MT6899_POWER_DOMAIN_ADSP_AO>;
	};

	disable-unused-pd-isp-traw@9f {
		compatible = "mediatek,scpsys-disable-unused";
		reg = <0x9f>;
		power-domains = <&hfrpsys MT6899_POWER_DOMAIN_ISP_TRAW>;
	};

	disable-unused-pd-isp-dip1@a0 {
		compatible = "mediatek,scpsys-disable-unused";
		reg = <0xa0>;
		power-domains = <&hfrpsys MT6899_POWER_DOMAIN_ISP_DIP1>;
	};

	disable-unused-pd-isp-main@a1 {
		compatible = "mediatek,scpsys-disable-unused";
		reg = <0xa1>;
		power-domains = <&hfrpsys MT6899_POWER_DOMAIN_ISP_MAIN>;
	};

	disable-unused-pd-isp-vcore@a2 {
		compatible = "mediatek,scpsys-disable-unused";
		reg = <0xa2>;
		power-domains = <&hfrpsys MT6899_POWER_DOMAIN_ISP_VCORE>;
	};

	disable-unused-pd-vde0@a3 {
		compatible = "mediatek,scpsys-disable-unused";
		reg = <0xa3>;
		power-domains = <&hfrpsys MT6899_POWER_DOMAIN_VDE0>;
	};

	disable-unused-pd-vde1@a4 {
		compatible = "mediatek,scpsys-disable-unused";
		reg = <0xa4>;
		power-domains = <&hfrpsys MT6899_POWER_DOMAIN_VDE1>;
	};

	disable-unused-pd-ven0@a5 {
		compatible = "mediatek,scpsys-disable-unused";
		reg = <0xa5>;
		power-domains = <&hfrpsys MT6899_POWER_DOMAIN_VEN0>;
	};

	disable-unused-pd-ven1@a6 {
		compatible = "mediatek,scpsys-disable-unused";
		reg = <0xa6>;
		power-domains = <&hfrpsys MT6899_POWER_DOMAIN_VEN1>;
	};

	disable-unused-pd-cam-mraw@a7 {
		compatible = "mediatek,scpsys-disable-unused";
		reg = <0xa7>;
		power-domains = <&hfrpsys MT6899_POWER_DOMAIN_CAM_MRAW>;
	};

	disable-unused-pd-cam-suba@a8 {
		compatible = "mediatek,scpsys-disable-unused";
		reg = <0xa8>;
		power-domains = <&hfrpsys MT6899_POWER_DOMAIN_CAM_SUBA>;
	};

	disable-unused-pd-cam-subb@a9 {
		compatible = "mediatek,scpsys-disable-unused";
		reg = <0xa9>;
		power-domains = <&hfrpsys MT6899_POWER_DOMAIN_CAM_SUBB>;
	};

	disable-unused-pd-cam-subc@aa {
		compatible = "mediatek,scpsys-disable-unused";
		reg = <0xaa>;
		power-domains = <&hfrpsys MT6899_POWER_DOMAIN_CAM_SUBC>;
	};

	disable-unused-pd-cam-main@ab {
		compatible = "mediatek,scpsys-disable-unused";
		reg = <0xab>;
		power-domains = <&hfrpsys MT6899_POWER_DOMAIN_CAM_MAIN>;
	};

	disable-unused-pd-cam-vcore@ac {
		compatible = "mediatek,scpsys-disable-unused";
		reg = <0xac>;
		power-domains = <&hfrpsys MT6899_POWER_DOMAIN_CAM_VCORE>;
	};

	disable-unused-pd-cam-ccu@ad {
		compatible = "mediatek,scpsys-disable-unused";
		reg = <0xad>;
		power-domains = <&hfrpsys MT6899_POWER_DOMAIN_CAM_CCU>;
	};

	disable-unused-pd-cam-ccu-ao@ae {
		compatible = "mediatek,scpsys-disable-unused";
		reg = <0xae>;
		power-domains = <&hfrpsys MT6899_POWER_DOMAIN_CAM_CCU_AO>;
	};

	disable-unused-pd-disp-vcore@af {
		compatible = "mediatek,scpsys-disable-unused";
		reg = <0xaf>;
		power-domains = <&hfrpsys MT6899_POWER_DOMAIN_DISP_VCORE>;
	};

	disable-unused-pd-mml0-shutdown@b0 {
		compatible = "mediatek,scpsys-disable-unused";
		reg = <0xb0>;
		power-domains = <&hfrpsys MT6899_POWER_DOMAIN_MML0_SHUTDOWN>;
	};

	disable-unused-pd-mml1-shutdown@b1 {
		compatible = "mediatek,scpsys-disable-unused";
		reg = <0xb1>;
		power-domains = <&hfrpsys MT6899_POWER_DOMAIN_MML1_SHUTDOWN>;
	};

	disable-unused-pd-dis0-shutdown@b2 {
		compatible = "mediatek,scpsys-disable-unused";
		reg = <0xb2>;
		power-domains = <&hfrpsys MT6899_POWER_DOMAIN_DIS0_SHUTDOWN>;
	};

	disable-unused-pd-dis1-shutdown@b3 {
		compatible = "mediatek,scpsys-disable-unused";
		reg = <0xb3>;
		power-domains = <&hfrpsys MT6899_POWER_DOMAIN_DIS1_SHUTDOWN>;
	};

	disable-unused-pd-ovl0-shutdown@b4 {
		compatible = "mediatek,scpsys-disable-unused";
		reg = <0xb4>;
		power-domains = <&hfrpsys MT6899_POWER_DOMAIN_OVL0_SHUTDOWN>;
	};

	disable-unused-pd-mm-infra@b5 {
		compatible = "mediatek,scpsys-disable-unused";
		reg = <0xb5>;
		power-domains = <&hfrpsys MT6899_POWER_DOMAIN_MM_INFRA>;
	};

	disable-unused-pd-dp-tx@b6 {
		compatible = "mediatek,scpsys-disable-unused";
		reg = <0xb6>;
		power-domains = <&hfrpsys MT6899_POWER_DOMAIN_DP_TX>;
	};

	disable-unused-pd-csi-rx@b7 {
		compatible = "mediatek,scpsys-disable-unused";
		reg = <0xb7>;
		power-domains = <&hfrpsys MT6899_POWER_DOMAIN_CSI_RX>;
	};
};
